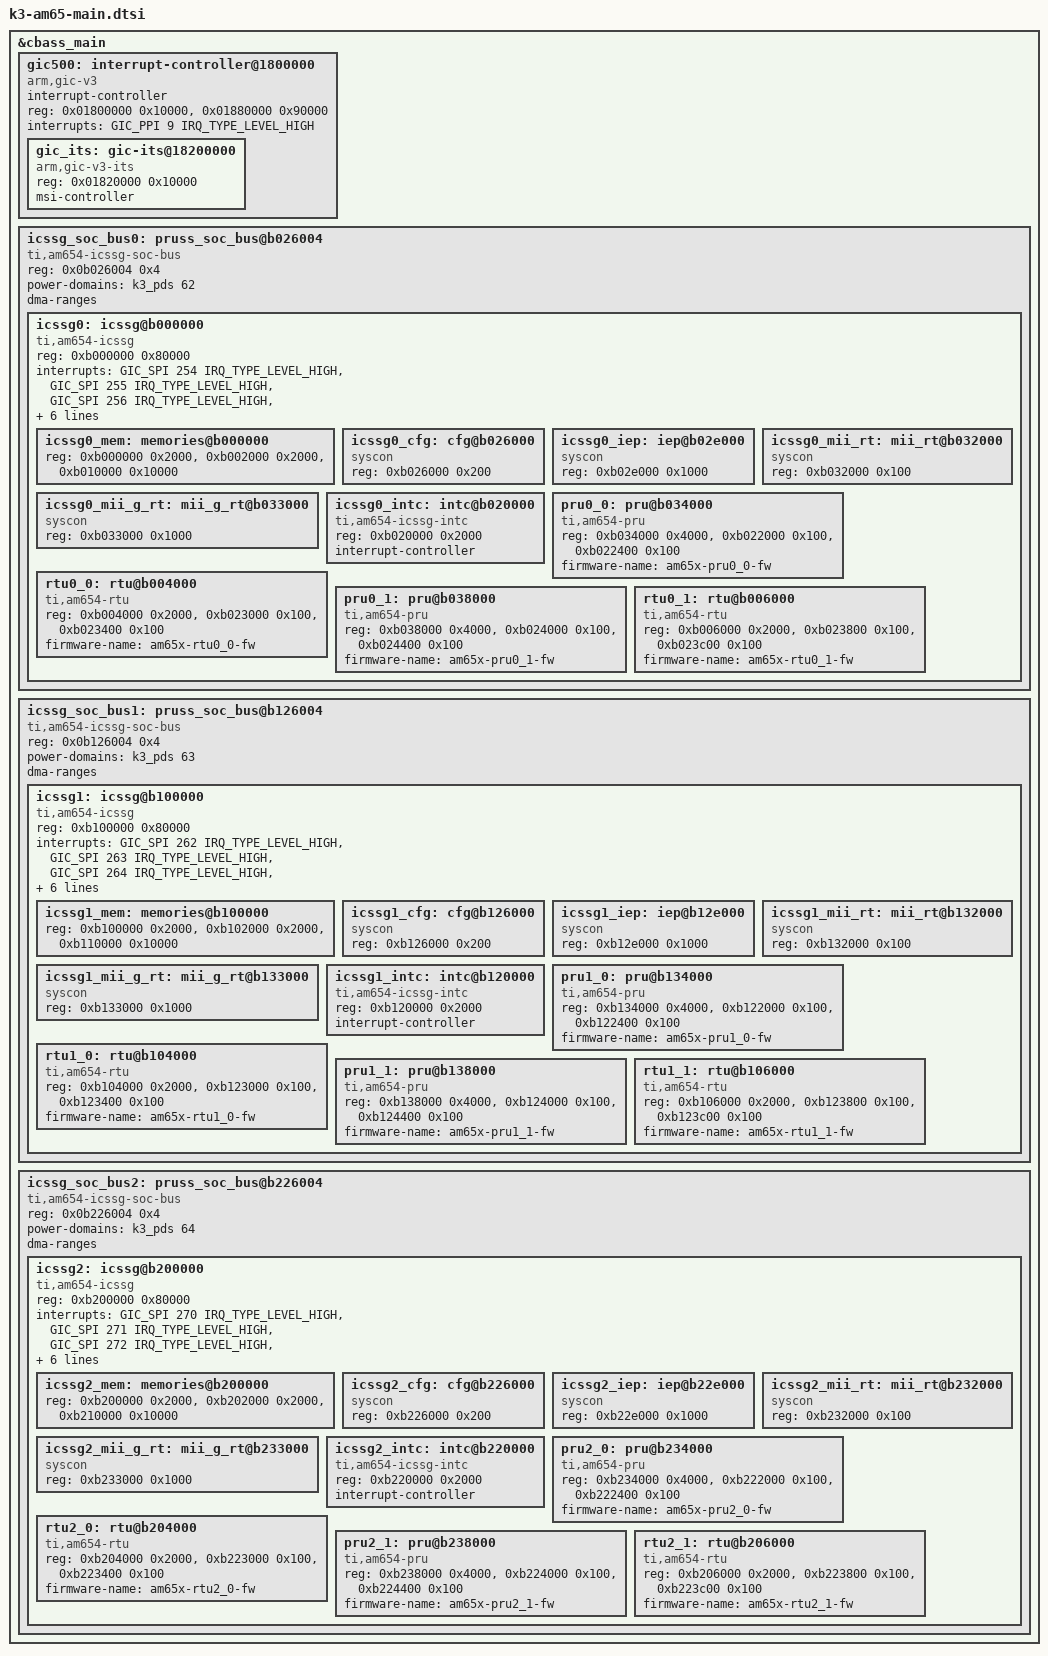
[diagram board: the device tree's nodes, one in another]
// SPDX-License-Identifier: GPL-2.0
/*
 * Device Tree Source for AM6 SoC Family Main Domain peripherals
 *
 * Copyright (C) 2016-2018 Texas Instruments Incorporated - http://www.ti.com/
 */

&cbass_main {
	gic500: interrupt-controller@1800000 {
		compatible = "arm,gic-v3";
		#address-cells = <1>;
		#size-cells = <1>;
		ranges;
		#interrupt-cells = <3>;
		interrupt-controller;
		reg = <0x01800000 0x10000>,	/* GICD */
		      <0x01880000 0x90000>;	/* GICR */
		/*
		 * vcpumntirq:
		 * virtual CPU interface maintenance interrupt
		 */
		interrupts = <GIC_PPI 9 IRQ_TYPE_LEVEL_HIGH>;

		gic_its: gic-its@18200000 {
			compatible = "arm,gic-v3-its";
			reg = <0x01820000 0x10000>;
			msi-controller;
			#msi-cells = <1>;
		};
	};

	icssg_soc_bus0: pruss_soc_bus@b026004 {
		compatible = "ti,am654-icssg-soc-bus";
		reg = <0x0b026004 0x4>;
		power-domains = <&k3_pds 62>;
		#address-cells = <1>;
		#size-cells = <1>;
		ranges;
		dma-ranges;

		icssg0: icssg@b000000 {
			compatible = "ti,am654-icssg";
			reg = <0xb000000 0x80000>;
			interrupts = <GIC_SPI 254 IRQ_TYPE_LEVEL_HIGH>,
				     <GIC_SPI 255 IRQ_TYPE_LEVEL_HIGH>,
				     <GIC_SPI 256 IRQ_TYPE_LEVEL_HIGH>,
				     <GIC_SPI 257 IRQ_TYPE_LEVEL_HIGH>,
				     <GIC_SPI 258 IRQ_TYPE_LEVEL_HIGH>,
				     <GIC_SPI 259 IRQ_TYPE_LEVEL_HIGH>,
				     <GIC_SPI 260 IRQ_TYPE_LEVEL_HIGH>,
				     <GIC_SPI 261 IRQ_TYPE_LEVEL_HIGH>;
			interrupt-names = "host2", "host3", "host4",
					  "host5", "host6", "host7",
					  "host8", "host9";
			#address-cells = <1>;
			#size-cells = <1>;
			ranges;
			dma-ranges;

			icssg0_mem: memories@b000000 {
				reg = <0xb000000 0x2000>,
				      <0xb002000 0x2000>,
				      <0xb010000 0x10000>;
				reg-names = "dram0", "dram1",
					    "shrdram2";
			};

			icssg0_cfg: cfg@b026000 {
				compatible = "syscon";
				reg = <0xb026000 0x200>;
			};

			icssg0_iep: iep@b02e000 {
				compatible = "syscon";
				reg = <0xb02e000 0x1000>;
			};

			icssg0_mii_rt: mii_rt@b032000 {
				compatible = "syscon";
				reg = <0xb032000 0x100>;
			};

			icssg0_mii_g_rt: mii_g_rt@b033000 {
				compatible = "syscon";
				reg = <0xb033000 0x1000>;
			};

			icssg0_intc: intc@b020000 {
				compatible = "ti,am654-icssg-intc";
				reg = <0xb020000 0x2000>;
				reg-names = "intc";
				interrupt-controller;
				#interrupt-cells = <1>;
			};

			pru0_0: pru@b034000 {
				compatible = "ti,am654-pru";
				reg = <0xb034000 0x4000>,
				      <0xb022000 0x100>,
				      <0xb022400 0x100>;
				reg-names = "iram", "control", "debug";
				firmware-name = "am65x-pru0_0-fw";
			};

			rtu0_0: rtu@b004000 {
				compatible = "ti,am654-rtu";
				reg = <0xb004000 0x2000>,
				      <0xb023000 0x100>,
				      <0xb023400 0x100>;
				reg-names = "iram", "control", "debug";
				firmware-name = "am65x-rtu0_0-fw";
			};

			pru0_1: pru@b038000 {
				compatible = "ti,am654-pru";
				reg = <0xb038000 0x4000>,
				      <0xb024000 0x100>,
				      <0xb024400 0x100>;
				reg-names = "iram", "control", "debug";
				firmware-name = "am65x-pru0_1-fw";
			};

			rtu0_1: rtu@b006000 {
				compatible = "ti,am654-rtu";
				reg = <0xb006000 0x2000>,
				      <0xb023800 0x100>,
				      <0xb023c00 0x100>;
				reg-names = "iram", "control", "debug";
				firmware-name = "am65x-rtu0_1-fw";
			};
		};
	};

	icssg_soc_bus1: pruss_soc_bus@b126004 {
		compatible = "ti,am654-icssg-soc-bus";
		reg = <0x0b126004 0x4>;
		power-domains = <&k3_pds 63>;
		#address-cells = <1>;
		#size-cells = <1>;
		ranges;
		dma-ranges;

		icssg1: icssg@b100000 {
			compatible = "ti,am654-icssg";
			reg = <0xb100000 0x80000>;
			interrupts = <GIC_SPI 262 IRQ_TYPE_LEVEL_HIGH>,
				     <GIC_SPI 263 IRQ_TYPE_LEVEL_HIGH>,
				     <GIC_SPI 264 IRQ_TYPE_LEVEL_HIGH>,
				     <GIC_SPI 265 IRQ_TYPE_LEVEL_HIGH>,
				     <GIC_SPI 266 IRQ_TYPE_LEVEL_HIGH>,
				     <GIC_SPI 267 IRQ_TYPE_LEVEL_HIGH>,
				     <GIC_SPI 268 IRQ_TYPE_LEVEL_HIGH>,
				     <GIC_SPI 269 IRQ_TYPE_LEVEL_HIGH>;
			interrupt-names = "host2", "host3", "host4",
					  "host5", "host6", "host7",
					  "host8", "host9";
			#address-cells = <1>;
			#size-cells = <1>;
			ranges;
			dma-ranges;

			icssg1_mem: memories@b100000 {
				reg = <0xb100000 0x2000>,
				      <0xb102000 0x2000>,
				      <0xb110000 0x10000>;
				reg-names = "dram0", "dram1",
					    "shrdram2";
			};

			icssg1_cfg: cfg@b126000 {
				compatible = "syscon";
				reg = <0xb126000 0x200>;
			};

			icssg1_iep: iep@b12e000 {
				compatible = "syscon";
				reg = <0xb12e000 0x1000>;
			};

			icssg1_mii_rt: mii_rt@b132000 {
				compatible = "syscon";
				reg = <0xb132000 0x100>;
			};

			icssg1_mii_g_rt: mii_g_rt@b133000 {
				compatible = "syscon";
				reg = <0xb133000 0x1000>;
			};

			icssg1_intc: intc@b120000 {
				compatible = "ti,am654-icssg-intc";
				reg = <0xb120000 0x2000>;
				reg-names = "intc";
				interrupt-controller;
				#interrupt-cells = <1>;
			};

			pru1_0: pru@b134000 {
				compatible = "ti,am654-pru";
				reg = <0xb134000 0x4000>,
				      <0xb122000 0x100>,
				      <0xb122400 0x100>;
				reg-names = "iram", "control", "debug";
				firmware-name = "am65x-pru1_0-fw";
			};

			rtu1_0: rtu@b104000 {
				compatible = "ti,am654-rtu";
				reg = <0xb104000 0x2000>,
				      <0xb123000 0x100>,
				      <0xb123400 0x100>;
				reg-names = "iram", "control", "debug";
				firmware-name = "am65x-rtu1_0-fw";
			};

			pru1_1: pru@b138000 {
				compatible = "ti,am654-pru";
				reg = <0xb138000 0x4000>,
				      <0xb124000 0x100>,
				      <0xb124400 0x100>;
				reg-names = "iram", "control", "debug";
				firmware-name = "am65x-pru1_1-fw";
			};

			rtu1_1: rtu@b106000 {
				compatible = "ti,am654-rtu";
				reg = <0xb106000 0x2000>,
				      <0xb123800 0x100>,
				      <0xb123c00 0x100>;
				reg-names = "iram", "control", "debug";
				firmware-name = "am65x-rtu1_1-fw";
			};
		};
	};

	icssg_soc_bus2: pruss_soc_bus@b226004 {
		compatible = "ti,am654-icssg-soc-bus";
		reg = <0x0b226004 0x4>;
		power-domains = <&k3_pds 64>;
		#address-cells = <1>;
		#size-cells = <1>;
		ranges;
		dma-ranges;

		icssg2: icssg@b200000 {
			compatible = "ti,am654-icssg";
			reg = <0xb200000 0x80000>;
			interrupts = <GIC_SPI 270 IRQ_TYPE_LEVEL_HIGH>,
				     <GIC_SPI 271 IRQ_TYPE_LEVEL_HIGH>,
				     <GIC_SPI 272 IRQ_TYPE_LEVEL_HIGH>,
				     <GIC_SPI 273 IRQ_TYPE_LEVEL_HIGH>,
				     <GIC_SPI 274 IRQ_TYPE_LEVEL_HIGH>,
				     <GIC_SPI 275 IRQ_TYPE_LEVEL_HIGH>,
				     <GIC_SPI 276 IRQ_TYPE_LEVEL_HIGH>,
				     <GIC_SPI 277 IRQ_TYPE_LEVEL_HIGH>;
			interrupt-names = "host2", "host3", "host4",
					  "host5", "host6", "host7",
					  "host8", "host9";
			#address-cells = <1>;
			#size-cells = <1>;
			ranges;
			dma-ranges;

			icssg2_mem: memories@b200000 {
				reg = <0xb200000 0x2000>,
				      <0xb202000 0x2000>,
				      <0xb210000 0x10000>;
				reg-names = "dram0", "dram1",
					    "shrdram2";
			};

			icssg2_cfg: cfg@b226000 {
				compatible = "syscon";
				reg = <0xb226000 0x200>;
			};

			icssg2_iep: iep@b22e000 {
				compatible = "syscon";
				reg = <0xb22e000 0x1000>;
			};

			icssg2_mii_rt: mii_rt@b232000 {
				compatible = "syscon";
				reg = <0xb232000 0x100>;
			};

			icssg2_mii_g_rt: mii_g_rt@b233000 {
				compatible = "syscon";
				reg = <0xb233000 0x1000>;
			};

			icssg2_intc: intc@b220000 {
				compatible = "ti,am654-icssg-intc";
				reg = <0xb220000 0x2000>;
				reg-names = "intc";
				interrupt-controller;
				#interrupt-cells = <1>;
			};

			pru2_0: pru@b234000 {
				compatible = "ti,am654-pru";
				reg = <0xb234000 0x4000>,
				      <0xb222000 0x100>,
				      <0xb222400 0x100>;
				reg-names = "iram", "control", "debug";
				firmware-name = "am65x-pru2_0-fw";
			};

			rtu2_0: rtu@b204000 {
				compatible = "ti,am654-rtu";
				reg = <0xb204000 0x2000>,
				      <0xb223000 0x100>,
				      <0xb223400 0x100>;
				reg-names = "iram", "control", "debug";
				firmware-name = "am65x-rtu2_0-fw";
			};

			pru2_1: pru@b238000 {
				compatible = "ti,am654-pru";
				reg = <0xb238000 0x4000>,
				      <0xb224000 0x100>,
				      <0xb224400 0x100>;
				reg-names = "iram", "control", "debug";
				firmware-name = "am65x-pru2_1-fw";
			};

			rtu2_1: rtu@b206000 {
				compatible = "ti,am654-rtu";
				reg = <0xb206000 0x2000>,
				      <0xb223800 0x100>,
				      <0xb223c00 0x100>;
				reg-names = "iram", "control", "debug";
				firmware-name = "am65x-rtu2_1-fw";
			};
		};
	};
};
